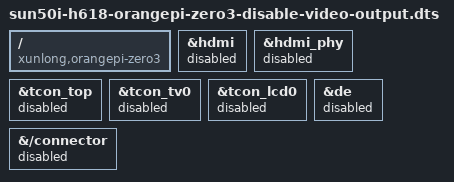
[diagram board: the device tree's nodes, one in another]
/dts-v1/;
/plugin/;

/ {
	compatible = "xunlong,orangepi-zero3";
	fragment@0 {
		target = <&hdmi>;
		__overlay__ {
			status = "disabled";
		};
	};

	fragment@1 {
		target = <&hdmi_phy>;
		__overlay__ {
			status = "disabled";
		};
	};

	fragment@2 {
		target = <&tcon_top>;
		__overlay__ {
			status = "disabled";
		};
	};

	fragment@3 {
		target = <&tcon_tv0>;
		__overlay__ {
			status = "disabled";
		};
	};

	fragment@4 {
		target = <&tcon_lcd0>;
		__overlay__ {
			status = "disabled";
		};
	};

	fragment@5 {
		target = <&de>;
		__overlay__ {
			status = "disabled";
		};
	};

	fragment@6 {
		target-path = "/connector";
		__overlay__ {
			status = "disabled";
		};
	};
};
